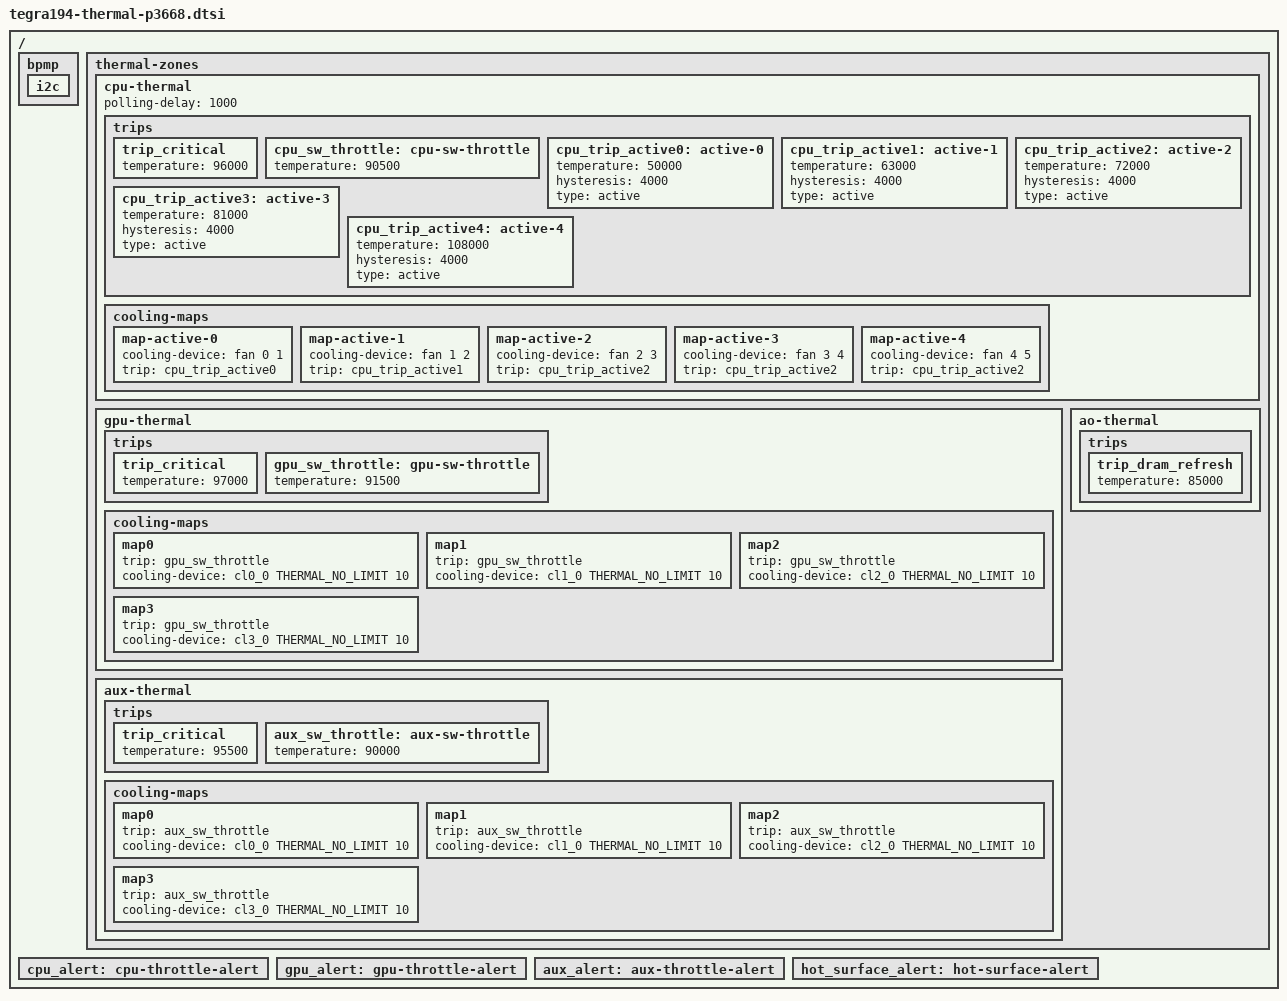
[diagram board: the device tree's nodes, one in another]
/*
 * Copyright (c) 2019-2023, NVIDIA CORPORATION.  All rights reserved.
 *
 * This program is free software; you can redistribute it and/or modify
 * it under the terms of the GNU General Public License as published by
 * the Free Software Foundation; version 2 of the License.
 *
 * This program is distributed in the hope that it will be useful, but WITHOUT
 * ANY WARRANTY; without even the implied warranty of MERCHANTABILITY or
 * FITNESS FOR A PARTICULAR PURPOSE.  See the GNU General Public License for
 * more details.
 */

#include <t19x-common-platforms/tegra194-thermal.dtsi>
#include <t19x-common-platforms/tegra194-thermal-userspace-alert.dtsi>
/ {
	bpmp { i2c {
		/delete-node/ temp-sensor@4c;
	};
	};
	thermal-zones {
		/delete-node/ Tboard_tegra;
		/delete-node/ Tdiode_tegra;
		cpu-thermal {
			polling-delay = <1000>;

			trips {
				trip_critical {
					temperature = <96000>;
				};
				cpu_sw_throttle: cpu-sw-throttle {
					temperature = <90500>;
				};
			};

			trips {
				cpu_trip_active0: active-0 {
					temperature = <50000>;
					hysteresis = <4000>;
					type = "active";
				};

				cpu_trip_active1: active-1 {
					temperature = <63000>;
					hysteresis = <4000>;
					type = "active";
				};

				cpu_trip_active2: active-2 {
					temperature = <72000>;
					hysteresis = <4000>;
					type = "active";
				};

				cpu_trip_active3: active-3 {
					temperature = <81000>;
					hysteresis = <4000>;
					type = "active";
				};

				cpu_trip_active4: active-4 {
					temperature = <108000>;
					hysteresis = <4000>;
					type = "active";
				};
			};

			cooling-maps {
				map-active-0 {
					cooling-device = <&fan 0 1>;
					trip = <&cpu_trip_active0>;
				};

				map-active-1 {
					cooling-device = <&fan 1 2>;
					trip = <&cpu_trip_active1>;
				};

				map-active-2 {
					cooling-device = <&fan 2 3>;
					trip = <&cpu_trip_active2>;
				};

				map-active-3 {
					cooling-device = <&fan 3 4>;
					trip = <&cpu_trip_active2>;
				};

				map-active-4 {
					cooling-device = <&fan 4 5>;
					trip = <&cpu_trip_active2>;
				};
			};
		};
		gpu-thermal {
			trips {
				trip_critical {
					temperature = <97000>;
				};
				gpu_sw_throttle: gpu-sw-throttle {
					temperature = <91500>;
				};
			};
			cooling-maps {
				map0 {
					trip = <&gpu_sw_throttle>;
					cooling-device = <&cl0_0 THERMAL_NO_LIMIT 10>;
				};
				map1 {
					trip = <&gpu_sw_throttle>;
					cooling-device = <&cl1_0 THERMAL_NO_LIMIT 10>;
				};
				map2 {
					trip = <&gpu_sw_throttle>;
					cooling-device = <&cl2_0 THERMAL_NO_LIMIT 10>;
				};
				map3 {
					trip = <&gpu_sw_throttle>;
					cooling-device = <&cl3_0 THERMAL_NO_LIMIT 10>;
				};
			};
		};
		aux-thermal {
			trips {
				trip_critical {
					temperature = <95500>;
				};
				aux_sw_throttle: aux-sw-throttle {
					temperature = <90000>;
				};
			};
			cooling-maps {
				map0 {
					trip = <&aux_sw_throttle>;
					cooling-device = <&cl0_0 THERMAL_NO_LIMIT 10>;
				};
				map1 {
					trip = <&aux_sw_throttle>;
					cooling-device = <&cl1_0 THERMAL_NO_LIMIT 10>;
				};
				map2 {
					trip = <&aux_sw_throttle>;
					cooling-device = <&cl2_0 THERMAL_NO_LIMIT 10>;
				};
				map3 {
					trip = <&aux_sw_throttle>;
					cooling-device = <&cl3_0 THERMAL_NO_LIMIT 10>;
				};
			};
		};
		ao-thermal {
			trips {
				trip_dram_refresh {
					temperature = <85000>;
				};
			};
		};
	};

	cpu_alert: cpu-throttle-alert {
		status = "okay";
	};

	gpu_alert: gpu-throttle-alert {
		status = "okay";
	};

	aux_alert: aux-throttle-alert {
		status = "okay";
	};

	hot_surface_alert: hot-surface-alert {
		status = "okay";
	};
};
